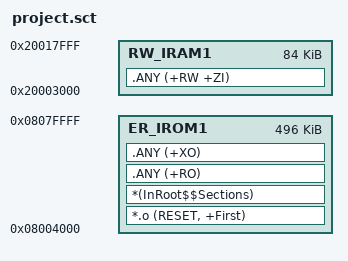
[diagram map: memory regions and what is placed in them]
; *************************************************************
; *** Scatter-Loading Description File generated by uVision ***
; *************************************************************

LR_IROM1 0x08004000 0x0007C000  {    ; load region size_region
  ER_IROM1 0x08004000 0x0007C000  {  ; load address = execution address
   *.o (RESET, +First)
   *(InRoot$$Sections)
   .ANY (+RO)
   .ANY (+XO)
  }
  RW_IRAM1 0x20003000 0x00015000  {  ; RW data
   .ANY (+RW +ZI)
  }
}

